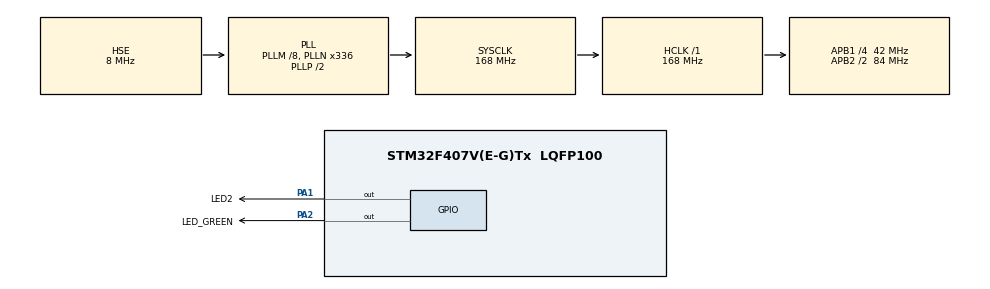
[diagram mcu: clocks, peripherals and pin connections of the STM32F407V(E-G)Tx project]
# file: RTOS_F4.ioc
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FREERTOS.Tasks01=led1_task,24,128,led1_task_handler,Default,NULL,Dynamic,NULL,NULL;led2_task,8,128,led2_task_handler,Default,NULL,Dynamic,NULL,NULL
FREERTOS.configUSE_NEWLIB_REENTRANT=0
Mcu.Family=STM32F4
Mcu.Name=STM32F407V(E-G)Tx
Mcu.Package=LQFP100
NVIC.PriorityGroup=NVIC_PRIORITYGROUP_4
NVIC.TIM7_IRQn=true\:15\:0\:false\:false\:true\:false\:false\:true\:true
NVIC.TimeBase=TIM7_IRQn
NVIC.TimeBaseIP=TIM7
PA1.GPIO_Label=LED2
PA1.Signal=GPIO_Output
PA13.Mode=Serial_Wire
PA13.Signal=SYS_JTMS-SWDIO
PA14.Mode=Serial_Wire
PA14.Signal=SYS_JTCK-SWCLK
PA2.GPIO_Label=LED_GREEN
PA2.Signal=GPIO_Output
PH0-OSC_IN.Mode=HSE-External-Oscillator
PH0-OSC_IN.Signal=RCC_OSC_IN
PH1-OSC_OUT.Mode=HSE-External-Oscillator
PH1-OSC_OUT.Signal=RCC_OSC_OUT
ProjectManager.HeapSize=0x200
ProjectManager.StackSize=0x400
ProjectManager.TargetToolchain=MDK-ARM V5.32
RCC.48MHZClocksFreq_Value=84000000
RCC.AHBFreq_Value=168000000
RCC.APB1CLKDivider=RCC_HCLK_DIV4
RCC.APB1Freq_Value=42000000
RCC.APB1TimFreq_Value=84000000
RCC.APB2CLKDivider=RCC_HCLK_DIV2
RCC.APB2Freq_Value=84000000
RCC.APB2TimFreq_Value=168000000
RCC.CortexFreq_Value=168000000
RCC.HCLKFreq_Value=168000000
RCC.HSE_VALUE=8000000
RCC.HSI_VALUE=16000000
RCC.LSE_VALUE=32768
RCC.PLLM=8
RCC.PLLN=336
RCC.PLLSourceVirtual=RCC_PLLSOURCE_HSE
RCC.SYSCLKFreq_VALUE=168000000
RCC.SYSCLKSource=RCC_SYSCLKSOURCE_PLLCLK
RCC.VCOOutputFreq_Value=336000000
VP_FREERTOS_VS_CMSIS_V2.Mode=CMSIS_V2
VP_SYS_VS_tim7.Mode=TIM7
board=custom

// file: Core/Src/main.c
/* USER CODE BEGIN Header */
/**
  ******************************************************************************
  * @file           : main.c
  * @brief          : Main program body
  ******************************************************************************
  * @attention
  *
  * Copyright (c) 2026 STMicroelectronics.
  * All rights reserved.
  *
  * This software is licensed under terms that can be found in the LICENSE file
  * in the root directory of this software component.
  * If no LICENSE file comes with this software, it is provided AS-IS.
  *
  ******************************************************************************
  */
/* USER CODE END Header */
#include "main.h"
#include "cmsis_os.h"
#include "gpio.h"

void SystemClock_Config(void);
void MX_FREERTOS_Init(void);

int main(void)
{

  /* MCU Configuration--------------------------------------------------------*/

  /* Reset of all peripherals, Initializes the Flash interface and the Systick. */
  HAL_Init();

  /* Configure the system clock */
  SystemClock_Config();

  /* Initialize all configured peripherals */
  MX_GPIO_Init();

  /* Init scheduler */
  osKernelInitialize(); //操作系统内核初始化 /* Call init function for freertos objects (in cmsis_os2.c) */
  MX_FREERTOS_Init();

  /* Start scheduler */
  osKernelStart();

  /* We should never get here as control is now taken by the scheduler */

  /* Infinite loop */
  while (1)
  {

  }
}

void SystemClock_Config(void)
{
  RCC_OscInitTypeDef RCC_OscInitStruct = {0};
  RCC_ClkInitTypeDef RCC_ClkInitStruct = {0};

  /** Configure the main internal regulator output voltage
  */
  __HAL_RCC_PWR_CLK_ENABLE();
  __HAL_PWR_VOLTAGESCALING_CONFIG(PWR_REGULATOR_VOLTAGE_SCALE1);

  /** Initializes the RCC Oscillators according to the specified parameters
  * in the RCC_OscInitTypeDef structure.
  */
  RCC_OscInitStruct.OscillatorType = RCC_OSCILLATORTYPE_HSE;
  RCC_OscInitStruct.HSEState = RCC_HSE_ON;
  RCC_OscInitStruct.PLL.PLLState = RCC_PLL_ON;
  RCC_OscInitStruct.PLL.PLLSource = RCC_PLLSOURCE_HSE;
  RCC_OscInitStruct.PLL.PLLM = 8;
  RCC_OscInitStruct.PLL.PLLN = 336;
  RCC_OscInitStruct.PLL.PLLP = RCC_PLLP_DIV2;
  RCC_OscInitStruct.PLL.PLLQ = 4;
  if (HAL_RCC_OscConfig(&RCC_OscInitStruct) != HAL_OK)
  {
    Error_Handler();
  }

  /** Initializes the CPU, AHB and APB buses clocks
  */
  RCC_ClkInitStruct.ClockType = RCC_CLOCKTYPE_HCLK|RCC_CLOCKTYPE_SYSCLK
                              |RCC_CLOCKTYPE_PCLK1|RCC_CLOCKTYPE_PCLK2;
  RCC_ClkInitStruct.SYSCLKSource = RCC_SYSCLKSOURCE_PLLCLK;
  RCC_ClkInitStruct.AHBCLKDivider = RCC_SYSCLK_DIV1;
  RCC_ClkInitStruct.APB1CLKDivider = RCC_HCLK_DIV4;
  RCC_ClkInitStruct.APB2CLKDivider = RCC_HCLK_DIV2;

  if (HAL_RCC_ClockConfig(&RCC_ClkInitStruct, FLASH_LATENCY_5) != HAL_OK)
  {
    Error_Handler();
  }
}

void HAL_TIM_PeriodElapsedCallback(TIM_HandleTypeDef *htim)
{
  if (htim->Instance == TIM7)
  {
    HAL_IncTick();
  }
}

void Error_Handler(void)
{
  __disable_irq();
  while (1)
  {
  }
}

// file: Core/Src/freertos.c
/* USER CODE BEGIN Header */
/**
  ******************************************************************************
  * File Name          : freertos.c
  * Description        : Code for freertos applications
  ******************************************************************************
  * @attention
  *
  * Copyright (c) 2026 STMicroelectronics.
  * All rights reserved.
  *
  * This software is licensed under terms that can be found in the LICENSE file
  * in the root directory of this software component.
  * If no LICENSE file comes with this software, it is provided AS-IS.
  *
  ******************************************************************************
  */
/* USER CODE END Header */

#include "FreeRTOS.h"
#include "task.h"
#include "main.h"
#include "cmsis_os.h"

/* Definitions for led1_task */
osThreadId_t led1_taskHandle;
const osThreadAttr_t led1_task_attributes = {
  .name = "led1_task",
  .stack_size = 128 * 4,
  .priority = (osPriority_t) osPriorityNormal,
};
/* Definitions for led2_task */
osThreadId_t led2_taskHandle;
const osThreadAttr_t led2_task_attributes = {
  .name = "led2_task",
  .stack_size = 128 * 4,
  .priority = (osPriority_t) osPriorityLow,
};

void led1_task_handler(void *argument);
void led2_task_handler(void *argument);

void MX_FREERTOS_Init(void); /* (MISRA C 2004 rule 8.1) */

void MX_FREERTOS_Init(void) {

  /* Create the thread(s) */
  /* creation of led1_task */
  led1_taskHandle = osThreadNew(led1_task_handler, NULL, &led1_task_attributes);

  /* creation of led2_task */
  led2_taskHandle = osThreadNew(led2_task_handler, NULL, &led2_task_attributes);

}

void led1_task_handler(void *argument)
{
  /* USER CODE BEGIN led1_task_handler */
  /* Infinite loop */
  for(;;)
  {
    HAL_GPIO_TogglePin(LED2_GPIO_Port, LED2_Pin);
    osDelay(500);
  }
  /* USER CODE END led1_task_handler */
}

void led2_task_handler(void *argument)
{
  /* USER CODE BEGIN led2_task_handler */
  /* Infinite loop */
  for(;;)
  {
    HAL_GPIO_TogglePin(LED_GREEN_GPIO_Port, LED_GREEN_Pin);
    osDelay(1000);
  }
  /* USER CODE END led2_task_handler */
}
